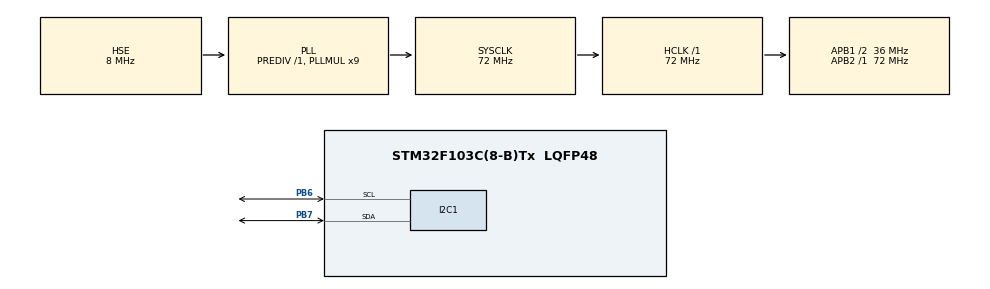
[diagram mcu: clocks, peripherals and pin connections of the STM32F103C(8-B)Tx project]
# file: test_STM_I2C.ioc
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I2C1.OwnAddress=0x12
Mcu.Family=STM32F1
Mcu.Name=STM32F103C(8-B)Tx
Mcu.Package=LQFP48
NVIC.I2C1_ER_IRQn=true\:0\:0\:false\:false\:true\:true\:true\:true
NVIC.I2C1_EV_IRQn=true\:0\:0\:false\:false\:true\:true\:true\:true
NVIC.PriorityGroup=NVIC_PRIORITYGROUP_4
PA13.Mode=Serial_Wire
PA13.Signal=SYS_JTMS-SWDIO
PA14.Mode=Serial_Wire
PA14.Signal=SYS_JTCK-SWCLK
PB6.Mode=I2C
PB6.Signal=I2C1_SCL
PB7.Mode=I2C
PB7.Signal=I2C1_SDA
PD0-OSC_IN.Mode=HSE-External-Oscillator
PD0-OSC_IN.Signal=RCC_OSC_IN
PD1-OSC_OUT.Mode=HSE-External-Oscillator
PD1-OSC_OUT.Signal=RCC_OSC_OUT
ProjectManager.HeapSize=0x200
ProjectManager.StackSize=0x400
ProjectManager.TargetToolchain=STM32CubeIDE
RCC.AHBFreq_Value=72000000
RCC.APB1CLKDivider=RCC_HCLK_DIV2
RCC.APB1Freq_Value=36000000
RCC.APB1TimFreq_Value=72000000
RCC.APB2Freq_Value=72000000
RCC.APB2TimFreq_Value=72000000
RCC.HCLKFreq_Value=72000000
RCC.PLLMUL=RCC_PLL_MUL9
RCC.PLLSourceVirtual=RCC_PLLSOURCE_HSE
RCC.SYSCLKFreq_VALUE=72000000
RCC.SYSCLKSource=RCC_SYSCLKSOURCE_PLLCLK
RCC.USBFreq_Value=72000000
board=custom

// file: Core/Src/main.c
/* USER CODE BEGIN Header */
/**
  ******************************************************************************
  * @file           : main.c
  * @brief          : Main program body
  ******************************************************************************
  * @attention
  *
  * Copyright (c) 2024 STMicroelectronics.
  * All rights reserved.
  *
  * This software is licensed under terms that can be found in the LICENSE file
  * in the root directory of this software component.
  * If no LICENSE file comes with this software, it is provided AS-IS.
  *
  ******************************************************************************
  */
/* USER CODE END Header */
#include "main.h"

/* USER CODE BEGIN Includes */
#include "stdint.h"
#include "math.h"
#include <string.h>
#include <stdio.h>

/* USER CODE END Includes */

/* USER CODE BEGIN PD */
#define RxSIZE 6
/* USER CODE END PD */

I2C_HandleTypeDef hi2c1;

/* USER CODE BEGIN PV */
uint8_t RxData[RxSIZE];
int32_t a ;
float dec;
uint8_t exponent;
uint64_t mu;
float real_num_array[30]; // Khai báo mảng để lưu trữ các giá trị real_num
uint8_t real_num_count =0  ; // Biến đếm số lượng giá trị real_num đã lưu
uint8_t bit_end = 0;
float Mang_A[50];
float real_num;
uint32_t Num_Array = 0 ;

/* USER CODE END PV */

void SystemClock_Config(void);
static void MX_GPIO_Init(void);
static void MX_I2C1_Init(void);

/* USER CODE BEGIN 0 */
void HAL_I2C_SlaveRxCpltCallback(I2C_HandleTypeDef *hi2c){
	HAL_I2C_Slave_Receive_IT(&hi2c1, RxData, RxSIZE);
	a = ((uint32_t)RxData[0] << 24) |
			((uint32_t)RxData[1] << 16) |
			((uint32_t)RxData[2] << 8) |
			(uint32_t)RxData[3];

	// Get the exponent value from RxData
	exponent = RxData[4];

	// Calculate mu and real_num values
	mu = pow(10, exponent);
	real_num = (float)((float)a/ mu);

	if (RxData[5] == 0xA5){
		real_num_array[real_num_count] = real_num;
		for(int i = real_num_count + 1; i<30; i++){
			real_num_array[i] = 0;
		}
		bit_end = 1;
	}

	else if(RxData[5] == 0x01 && bit_end == 0){
		real_num_array[real_num_count] = real_num;
		real_num_count++;
	}
}

void HAL_I2C_AddrCallback(I2C_HandleTypeDef*hi2c,uint8_t TransferDirection,uint16_t AddrMatchCode)
{
		if(TransferDirection == I2C_DIRECTION_TRANSMIT)
		{
			HAL_I2C_Slave_Sequential_Receive_IT(hi2c,RxData, RxSIZE,I2C_FIRST_AND_LAST_FRAME);
		}
		else
		{
		Error_Handler();
		}
}

/* USER CODE END 0 */

int main(void)
{

  /* MCU Configuration--------------------------------------------------------*/

  /* Reset of all peripherals, Initializes the Flash interface and the Systick. */
  HAL_Init();

  /* Configure the system clock */
  SystemClock_Config();

  /* Initialize all configured peripherals */
  MX_GPIO_Init();
  MX_I2C1_Init();
  /* USER CODE BEGIN 2 */
  void HAL_I2C_SlaveRxCpltCallback(I2C_HandleTypeDef *hi2c);
  void HAL_I2C_AddrCallback(I2C_HandleTypeDef*hi2c,uint8_t TransferDirection,uint16_t AddrMatchCode);

  HAL_I2C_EnableListen_IT(&hi2c1);

  /* USER CODE END 2 */

  /* Infinite loop */
  while (1)
  {
	  HAL_I2C_SlaveRxCpltCallback(&hi2c1);
  }
}

void SystemClock_Config(void)
{
  RCC_OscInitTypeDef RCC_OscInitStruct = {0};
  RCC_ClkInitTypeDef RCC_ClkInitStruct = {0};

  /** Initializes the RCC Oscillators according to the specified parameters
  * in the RCC_OscInitTypeDef structure.
  */
  RCC_OscInitStruct.OscillatorType = RCC_OSCILLATORTYPE_HSE;
  RCC_OscInitStruct.HSEState = RCC_HSE_ON;
  RCC_OscInitStruct.HSEPredivValue = RCC_HSE_PREDIV_DIV1;
  RCC_OscInitStruct.HSIState = RCC_HSI_ON;
  RCC_OscInitStruct.PLL.PLLState = RCC_PLL_ON;
  RCC_OscInitStruct.PLL.PLLSource = RCC_PLLSOURCE_HSE;
  RCC_OscInitStruct.PLL.PLLMUL = RCC_PLL_MUL9;
  if (HAL_RCC_OscConfig(&RCC_OscInitStruct) != HAL_OK)
  {
    Error_Handler();
  }

  /** Initializes the CPU, AHB and APB buses clocks
  */
  RCC_ClkInitStruct.ClockType = RCC_CLOCKTYPE_HCLK|RCC_CLOCKTYPE_SYSCLK
                              |RCC_CLOCKTYPE_PCLK1|RCC_CLOCKTYPE_PCLK2;
  RCC_ClkInitStruct.SYSCLKSource = RCC_SYSCLKSOURCE_PLLCLK;
  RCC_ClkInitStruct.AHBCLKDivider = RCC_SYSCLK_DIV1;
  RCC_ClkInitStruct.APB1CLKDivider = RCC_HCLK_DIV2;
  RCC_ClkInitStruct.APB2CLKDivider = RCC_HCLK_DIV1;

  if (HAL_RCC_ClockConfig(&RCC_ClkInitStruct, FLASH_LATENCY_2) != HAL_OK)
  {
    Error_Handler();
  }
}

static void MX_I2C1_Init(void)
{

  hi2c1.Instance = I2C1;
  hi2c1.Init.ClockSpeed = 100000;
  hi2c1.Init.DutyCycle = I2C_DUTYCYCLE_2;
  hi2c1.Init.OwnAddress1 = 36;
  hi2c1.Init.AddressingMode = I2C_ADDRESSINGMODE_7BIT;
  hi2c1.Init.DualAddressMode = I2C_DUALADDRESS_DISABLE;
  hi2c1.Init.OwnAddress2 = 0;
  hi2c1.Init.GeneralCallMode = I2C_GENERALCALL_DISABLE;
  hi2c1.Init.NoStretchMode = I2C_NOSTRETCH_DISABLE;
  if (HAL_I2C_Init(&hi2c1) != HAL_OK)
  {
    Error_Handler();
  }

}

static void MX_GPIO_Init(void)
{

  /* GPIO Ports Clock Enable */
  __HAL_RCC_GPIOD_CLK_ENABLE();
  __HAL_RCC_GPIOA_CLK_ENABLE();
  __HAL_RCC_GPIOB_CLK_ENABLE();

}

void Error_Handler(void)
{
  __disable_irq();
  while (1)
  {
  }
}
